# S32R372 register map
Vendor: Freescale Semiconductor, Inc.; Series: Qorivva; File version: 1.6
Registers are 32-bit, read-write, reset 0x0 unless marked. A register's access mark holds for its fields unless they carry their own. Offsets are from the block's base; [hi:lo] are bit positions; {n}, {i} and the like mark numbered series.

## LINFlexD_1 — LINFlexD
Base 0xFFE90000; register names take the prefix LINFlexD_1_
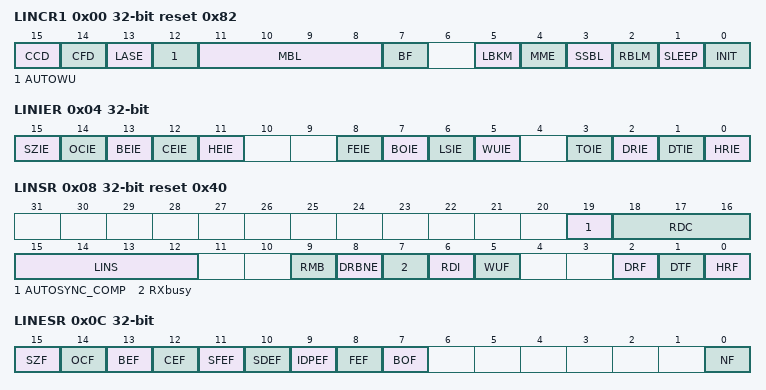
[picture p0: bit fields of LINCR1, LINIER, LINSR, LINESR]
0x00 LINCR1 reset 0x82 — LIN Control Register 1
  [15] CCD — Checksum Calculation disable This bit can be written during Initialization mode only
    0=Checksum calculation is done by hardware. When this bit is reset the LINCFR register is read only.; 1=Checksum calculation is disabled. When this bit is set the LINCFR register is read/write. User can program this register to sent a software calculated checksum/CRC (provided CFD is reset).
  [14] CFD — Checksum field disable This bit can be configured during Initialization mode only
    0=Checksum field is sent after the required number of data bytes are sent; 1=No checksum field is sent in the frame
  [13] LASE — LIN Autosynchronization Enable This bit can be programmed in Initialization mode only
    0=Autosynchronization disabled; 1=Autosynchronization enabled
  [12] AUTOWU — Auto Wakeup This bit can be configured during Initialization mode only
    0=Sleep bit is cleared by software only; 1=Sleep bit gets cleared by hardware whenever WUF bit of LINSR is set
  [11:8] MBL — Master Break Length These bits choose the length of the Sync break to be generated by the master
    {v}={v+10}-bit break length (v=0..13); 14=36-bit (cooling) break length; 15=50-bit break length
  [7] BF — By-pass filter This bit can be programmed during Initialization mode only
    0=No IRQ if ID does not match any filter; 1=A RX IRQ is generated on ID not matching any filter
  [5] LBKM — Loop Back mode Refer to "Loop back mode" in Test mode
    0=Loop Back Mode disabled; 1=Loop Back mode enabled
  [4] MME — Master mode enable This bit can be programmed in Initialization mode only
    0=Slave Mode; 1=Master Mode
  [3] SSBL — Slave Mode Sync Break Length This bit can be programmed in Initialization mode only
    0=11 bit break length; 1=10 bit break length
  [2] RBLM — Receiver Buffer Locked mode This bit can be programmed in Initialization mode only
    0=Receiver Buffer not locked, next incoming message will overwrite the old one; 1=Receiver buffer locked against overrun. Once the buffer is full the next incoming message will be discarded if buffer is not released - in other words, RMB is not reset by software.
  [1] SLEEP — Sleep Mode Request This bit is set by software to request LINFlexD to enter Sleep mode
  [0] INIT — Initialization Mode Request The software sets this bit to switch the hardware into Initialization mode
0x04 LINIER — LIN Interrupt enable register
  [15] SZIE — Stuck at zero Interrupt Enable An interrupt is generated if this bit is set and the Stuck at Zero Flag (SZF) in LINESR or UARTSR is set
    0=No interrupt; 1=Interrupt enabled
  [14] OCIE — Output Compare Interrupt Enable
    0=No interrupt; 1=Interrupt generated when OCF bit in LINESR or UARTSR is set
  [13] BEIE — Bit Error Interrupt Enable
    0=No interrupt; 1=Interrupt generated when BEF bit in LINESR is set
  [12] CEIE — Checksum Error Interrupt Enable An interrupt is generated if this bit is set and the Checksum Error Flag (CEF) is set in LINESR
    0=No interrupt; 1=Interrupt enabled
  [11] HEIE — Header Error Interrupt Enable An interrupt is generated when this bit is set and either of the following flags are set SFEF, SDEF, IDPEF in LINESR are set
    0=No interrupt; 1=Interrupt enabled
  [8] FEIE — Frame Error Interrupt Enable
    0=No interrupt; 1=Interrupt generated if Frame Error Flag (FEF) bit is set in LINESR or UARTSR
  [7] BOIE — Buffer Overrun Error Interrupt Enable An interrupt is generated if this bit is set and the Buffer Overrun Flag (BOF) is set in LINESR or UARTSR
    0=No interrupt; 1=Interrupt enabled
  [6] LSIE — LIN state Interrupt enable Interrupt is generated only when entering the above fields
    0=No interrupt; 1=Interrupt generated on entering the following states: Sync Del, Sync Field, Identifier field, Checksum
  [5] WUIE — Wakeup interrupt enable If this bit is set and the WUF in LINSR or UARTSR is set then an interrupt is generated
    0=No interrupt; 1=Interrupt enabled
  [3] TOIE — Timeout Interrupt Enable An interrupt is generated if this bit is set and UARTSR[TO] status bit is set (in UART mode)
    0=No interrupt; 1=Interrupt enabled
  [2] DRIE — Data Reception complete Interrupt enable An interrupt is generated when this bit is set and Data Received flag (DRF) in LINSR or UARTSR is set
    0=No interrupt; 1=Interrupt enabled
  [1] DTIE — Data Transmitted Interrupt enable An interrupt is generated when this bit is set and Data Transmitted flag (DTF) in LINSR or UARTSR is set
    0=No interrupt; 1=Interrupt enabled
  [0] HRIE — Header Received Interrupt An interrupt is generated when this bit is set and the Header Received flag (HRF) in LINSR is set
    0=No interrupt; 1=Interrupt enabled
0x08 LINSR reset 0x40 — LIN Status Register
  [19] AUTOSYNC_COMP — AUTOSYNC_COMP This bit is set after autosynchronization is complete and when the LASE bit in LINCR1 register is enabled
  [18:16] RDC ro — Receive Data Byte Count RDC contains the number of entries (bytes) in the Receive data buffer in LIN mode
    0=1 byte; {v}={v+1} bytes (v=1..7)
  [15:12] LINS ro — LIN state
    0=Sleep mode: LINFlexD is in Sleep mode, to save power consumption; 1=Init mode: LINFlexD is in Initialization mode; 2=Idle mode: This mode is entered when: SLEEP bit and INIT bit are reset by software; Wakeup pulse has been received on RX pin (AUTOWU set); Previous frame transmission/reception has been completed/aborted; 3=Sync break: In slave mode, a falling edge followed by a dominant state has been detected. Receiving sync break. In slave mode, a falling edge followed by a dominant state has been detected. Receiving sync break. In master mode, sync break transmission ongoing. Note: In slave mode upon any error LIN state could be either Idle or Rec Break, depending on last bit detected on LIN_RX. If last bit detected is dominant then Rec_Break, otherwise Idle.; 4=Sync Del: In Slave mode, valid Sync break has been detected (10 bit or 11 bit). Waiting for a rising edge. In Master mode, Sync break transmission has been completed, sync delimiter transmission is ongoing.; 5=Sync Field: In Slave mode, a valid sync Del has been detected (recessive state for at least one bit time). Receiving sync field. In Master mode, sync field transmission ongoing.; 6=Identifier Field: In Slave mode, a valid sync field has been received. Receiving ID field. In Master mode, identifier transmission is ongoing.; 7=Header Reception/Transmission: In Slave mode, a valid header has been received and Identifier field is available in the BIDR. In Master mode, header transmitted.; 8=Data Reception/Data Transmission: In Receiver mode, reception ongoing. In Transmitter mode, response transmission ongoing.; 9=Checksum: Data transmission/reception completed, checksum transmission/reception ongoing
  [9] RMB — Release Message Buffer
    0=Buffer data is free. Reset by hardware in when in Initialization mode; 1=Buffer data ready to be read by software. This bit should be cleared by software after reading the data received in the buffer.
  [8] DRBNE — Data Reception Buffer Not Empty Flag This bit is set by hardware as soon as the first byte of response has been received and stored in BDRL (when there is at least one data byte in reception buffer)
  [7] RXbusy ro — Receiver Busy flag In Slave mode after header reception, if DIR bit is reset and reception starts, then this bit is set
    0=Receiver is idle; 1=Reception ongoing
  [6] RDI ro — LIN Receive signal This bit reflects the current status of the Rx pin
  [5] WUF — Wakeup flag This bit is set by hardware when a falling edge is detected on the Rx pin
  [2] DRF — Data Reception Completed flag This bit is set by hardware and indicates that data reception has been completed
  [1] DTF — Data Transmission Completed flag This bit is set by hardware and indicates that data transmission is completed
  [0] HRF — Header Received flag This bit is set when the header reception is completed
0x0C LINESR — LIN Error Status Register
  [15] SZF — Stuck at Zero flag This bit is set when there is a stuck-at-zero timeout error
  [14] OCF — Output Compare Flag 0: No output compare event occurred 1: In master mode, LINESR[OCF] flag is set when counter LINTCSR[CNT] has matched the content of LINOCR[OC2]
  [13] BEF — Bit Error flag This bit is set by hardware when there is a bit error
  [12] CEF — Checksum Error flag This bit is set by hardware if the received checksum does not match the hardware-calculated checksum
  [11] SFEF — Sync Field Error flag This bit is set by hardware when the received Sync Field is inconsistent
  [10] SDEF — Sync Delimiter Error flag This bit is set by hardware when the delimiter is too short (in other words, less than one bit time)
  [9] IDPEF — ID Parity Error flag This bit is set by hardware when there is an error in the ID parity
  [8] FEF — Framing Error flag This bit is set by hardware when there is a framing error (invalid stop bit)
  [7] BOF — Buffer overrun flag This bit is set by hardware when there is a new byte received and RMB bit is not cleared
  [0] NF — Noise flag This bit is set by hardware when noise is detected in the received character
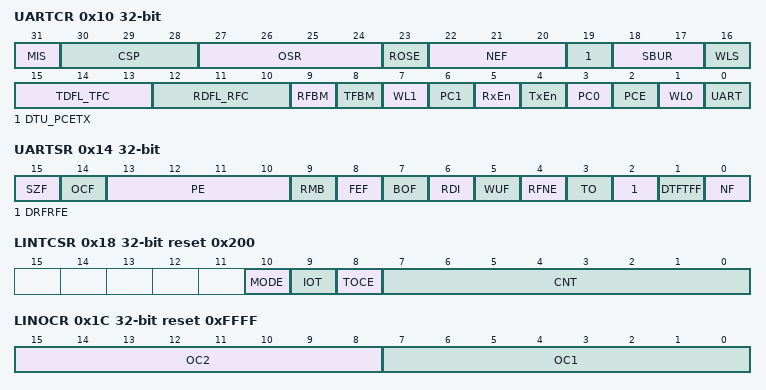
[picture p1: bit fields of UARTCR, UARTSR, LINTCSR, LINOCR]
0x10 UARTCR — UART Mode Control Register
  [31] MIS — Monitor Idle State Register bit can be read in any mode, written only in initialization mode.
    0=UARTCTO monitors the number of bits to be received; 1=UARTCTO monitors the idle state of the reception line
  [30:28] CSP — Configurable Sample Point (i) These bits will decide the sample point during reduced over sampling
  [27:24] OSR — Over Sampling Rate These bits are programmable by the user to configure the number of samples taken for a bit when reduced over sampling is enabled
  [23] ROSE — Reduced Over Sampling EnableRegister bit can be read in any mode, written only in initialization mode
    0=Each bit is over sampled sixteen times; 1=OSR bits decide the over sampling rate
  [22:20] NEF — Number of expected frame These bits are used to configure the number of expected frames in UART reception mode
  [19] DTU_PCETX — Disable Timeout in UART mode
    0=Timeout has to be handled by software; 1=Timeout in UART mode is disabled after the configured number of data frames are received
  [18:17] SBUR — Stop bits in UART reception mode When the UART is used for transmission and reception we have to set the same number of stop bits in GCR and SBUR
    0=1 stop bit; 1=2 stop bits; 2=3 stop bits
  [16] WLS — Special Word Length in UART mode This bit can be programmed in initialization mode only when the UART bit is set
    0=This bit is disabled; 1=This bit enables 12-bit + parity bit in reception (UART mode) for MSC (Micro Second Channel upstream frame) support
  [15:13] TDFL_TFC — Transmitter Data Field Length/TX FIFO Counter TDFL defines the number of bytes to be transmitted in UART buffer mode (TFBM = 0)
  [12:10] RDFL_RFC — Reception Data Field Length /RX FIFO Counter RDFL defines the number of bytes to be received in UART buffer mode (RFBM = 0)
  [9] RFBM — RFBM Rx Fifo/Buffer mode This bit can be programmed in Initialization mode, only when the UART bit is set
    0=Rx Buffer mode enabled; 1=Rx Fifo mode enabled (mandatory in DMA Rx mode)
  [8] TFBM — Tx Fifo/Buffer mode This bit can be programmed in initialization mode, only when the UART bit is set
    0=Tx Buffer mode enabled; 1=Tx Fifo mode enabled (mandatory in DMA Tx mode)
  [7] WL1 — Word Length in UART mode This bit can be programmed in Initialization mode only, when the UART bit is set
  [6] PC1 — Parity Control This bit can be programmed in Initialization mode, only when UART bit is set
  [5] RxEn — Receiver Enable This bit can be programmed only when the UART bit is set.
    0=Receiver disabled; 1=Receiver enabled
  [4] TxEn — Transmitter Enable This bit can be programmed only when UART bit is set.
    0=Transmitter disabled; 1=Transmitter enabled, transmission starts only when this bit is set and Data byte 0 (DATA0) is programmed
  [3] PC0 — Parity Control This bit can be programmed in Initialization mode, only when UART bit is set
  [2] PCE — Parity Control Enable This bit can be programmed in Initialization mode only, when the UART bit is set
    0=Parity transmit/check Disable; 1=Parity transmit/check Enable
  [1] WL0 — Word Length in UART mode This bit can be programmed in Initialization mode only, when UART bit is set
  [0] UART — UART Mode This bit can be programmed in Initialization mode only
    0=LIN mode; 1=UART mode
0x14 UARTSR — UART Mode Status Register
  [15] SZF — Stuck at Zero flag This bit is set by hardware when 100 dominant bits are detected
  [14] OCF — Output Compare Flag An interrupt will be generated if the OCIE bit in LINIER is set
    0=No output compare event occurred; 1=The content of the counter has matched the content of LINOCR
  [13:10] PE — Parity Error flag These bits indicate if there is a Parity Error in the corresponding byte
    0=No parity error; 1=Parity error in the corresponding received byte
  [9] RMB — Release Message Buffer This bit should be cleared by software
    0=Buffer data is free; 1=Buffer data ready to be read by software
  [8] FEF — Framing Error flag This bit is set by hardware when there is a framing error (invalid stop bit)
  [7] BOF — FIFO/Buffer overrun flag This bit is set by hardware when there is a new byte received and the RMB bit is not cleared in UART buffer mode
  [6] RDI — Receiver Data Input signal This bit reflects the current status of the RX pin.
  [5] WUF — Wakeup flag This bit is set by hardware when a falling edge is detected on the RX pin in sleep mode
  [4] RFNE ro — Receive FIFO Not Empty RFNE bit is set by hardware in UART FIFO mode (RFBM = 1), when there is at least one data byte present in the receive FIFO
  [3] TO — Timeout This bit is set by hardware when a UART timeout occurs - in other words, the value of UARTCTO becomes equal to the preset value of the timeout (UARTPTO register setting)
  [2] DRFRFE — Data Reception Completed Flag /Rx FIFO Empty Flag DRF is set by hardware in UART buffer mode (RFBM = 0) and indicates that the number of bytes programmed in RDFL have been received
  [1] DTFTFF — Data Transmission Completed Flag/ TX FIFO Full Flag DTF is set by hardware in UART buffer mode (TFBM = 0) and indicates that data transmission is completed
  [0] NF — Noise flag This bit is set by hardware when noise is detected in the received character
0x18 LINTCSR reset 0x200 — LIN Time-Out Control Status Register
  [10] MODE — Time-out counter mode This bit can be configured only during initialization
    0=LIN mode; 1=Output compare mode
  [9] IOT — Idle on timeout Register bit can be read in any mode, written only in initialization mode
    0=LIN state machine does not reset to Idle on timeout; 1=LIN state machine resets to Idle on timeout event
  [8] TOCE — Time-out counter enable TOCE is always configurable by software in Initialization mode
    0=Time-out counter disable. OCF flag is not set on an output compare event.; 1=Time-out counter enable. OCF flag is set if an output compare event occurs.
  [7:0] CNT ro — Counter Value These bits reflect the value of a counter used for timeout
0x1C LINOCR reset 0xFFFF — LIN Output Compare Register
  [15:8] OC2 — Output compare value 2
  [7:0] OC1 — Output compare value 1
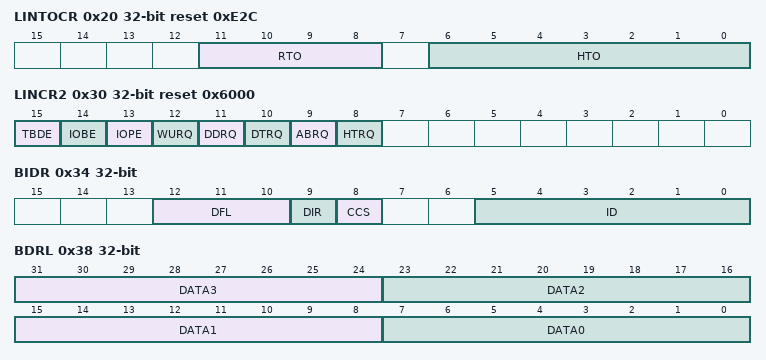
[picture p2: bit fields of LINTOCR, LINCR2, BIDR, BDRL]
0x20 LINTOCR reset 0xE2C — LIN Time-Out Control Register
  [11:8] RTO — Response timeout value This is the response timeout duration (in bit time) for 1 byte
  [6:0] HTO — Header timeout value This register contains the header timeout duration (in bit time)
0x24 LINFBRR — LIN Fractional Baud Rate Register
  [3:0] FBR — Fractional Baud rates Register bit can be read in any mode, written only in initialization mode.
    0=Fraction(LDIV) = 0; {v}=Fraction(LDIV) = {v}/16 (v=1..15)
0x28 LINIBRR — LIN Integer Baud Rate Register
  [19:0] IBR — Integer Baud rates These bits along with the fractional baud rate bits decide the LIN baud rate
0x2C LINCFR — LIN Checksum Field Register
  [7:0] CF — Checksum bits When the CCD bit is reset these bits are read-only and are calculated by hardware
0x30 LINCR2 reset 0x6000 — LIN Control Register 2
  [15] TBDE — Two Bit delimiter bit This bit can be set in Initialization mode only
    0=Delimiter length in break field is 1 bit; 1=Delimiter length in break field is 2 bits
  [14] IOBE — Idle on Bit Error This bit can be set in Initialization mode only
    0=Bit Error does not reset LIN state machine; 1=Bit Error resets LIN state machine
  [13] IOPE — Idle on Identifier Parity Error This bit can be set in Initialization mode only
    0=Parity Error does not reset LIN state machine; 1=Parity Error resets LIN state machine
  [12] WURQ — Wakeup Generate Request Setting this bit will generate a wakeup pulse
  [11] DDRQ — Data Discard request Set by software to stop data reception if the frame does not concern the node
  [10] DTRQ — Data Transmission Request Set by software in slave mode to request the transmission of the LIN Data field stored in the Buffer data register
  [9] ABRQ — Abort Request Set by software to abort the current transmission
  [8] HTRQ — Header Transmission Request Set by software to request the transmission of the LIN Header
0x34 BIDR — Buffer Identifier Register
  [12:10] DFL — Data Field Length Number of data bytes in the response part of the frame
  [9] DIR — Direction This bit controls the direction of the data field.
    0=LINFlexD receives the data and copy them in the BDR registers; 1=LINFlexD transmits the data from the BDR registers
  [8] CCS — Classic Checksum This bit controls the type of checksum applied on the current message.
    0=Enhanced Checksum covering Identifier and Data fields. This is compatible with LIN specification rev. 2.0 and higher.; 1=Classic Checksum covering Data filed only. This is compatible with LIN specification 1.3 and lower.
  [5:0] ID — Identifier Identifier part of the identifier field without the identifier parity
0x38 BDRL — Buffer Data Register Least Significant
  [31:24] DATA3 — Data Byte 3 Data byte 3 of the data field.
  [23:16] DATA2 — Data Byte 2 Data byte 2 of the data field.
  [15:8] DATA1 — Data Byte 1 Data byte 1of the data field.
  [7:0] DATA0 — Data Byte 0 Data byte 0 of the data field.
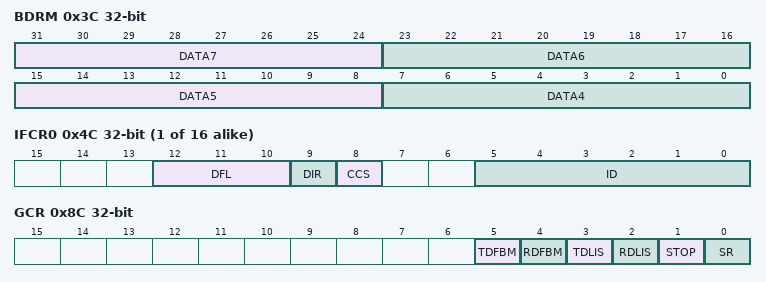
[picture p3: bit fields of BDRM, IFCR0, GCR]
0x3C BDRM — Buffer Data Register Most Significant
  [31:24] DATA7 — Data Byte 7 Data byte 7 of the data field.
  [23:16] DATA6 — Data Byte 6 Data byte 6 of the data field.
  [15:8] DATA5 — Data Byte 5 Data byte 5of the data field.
  [7:0] DATA4 — Data Byte 4 Data byte 4 of the data field.
0x40 IFER — Identifier Filter Enable Register
  [15:0] FACT — Filter active The software sets the bit FACT[x] to activate the filter x in Identifier list mode
0x44 IFMI ro — Identifier Filter Match Index
  [4:0] IFMI — Filter match index Upon a filter match with xth filter - IFMI[4:0] = x+1
0x48 IFMR — Identifier Filter Mode Register
  [7:0] IFM — Filter mode Register bit can be read in any mode, written only in initialization mode.
    0=Filters 2n and 2n+1 are in identifier list mode; 1=Filters 2n and 2n+1 are in mask mode, where filter 2n+1 is the mask for filter 2n
{0x4C+4i} IFCR{i} (i=0..15) — Identifier Filter Control Register
  [12:10] DFL — Data Field Length
  [9] DIR — Direction
    0=LINFlexD receives data and copies to the BDR registers; 1=LINFlexD transmits data from the BDR registers
  [8] CCS — Classic Checksum
    0=Enhanced Checksum covering Identifier and Data fields. This is compatible with LIN specification rev. 2.0 and higher.; 1=Classic Checksum covering Data field only. This is compatible with LIN specification 1.3 and lower.
  [5:0] ID — Identifier
0x8C GCR — Global Control Register
  [5] TDFBM — Transmit data first bit MSB This bit controls the first bit of transmit data (payload only) as MSB/LSB in both UART and LIN modes
    0=The first bit of transmitted data is LSB - in other words, the first bit transmitted is mapped on LSB bit (BDR (0), BDR (8), BDR (16), BDR (24)); 1=The first bit of transmitted data is MSB - in other words, the first bit transmitted is mapped on MSB bit (BDR (7), BDR (15), BDR (23), BDR (31))
  [4] RDFBM — Received data first bit MSB This bit controls the first bit of received data (payload only) as MSB/LSB both in UART and LIN modes
    0=The first bit of received data is LSB - in other words, the first bit received is mapped on LSB bit (BDR (0), BDR (8), BDR (16), BDR (24)); 1=The first bit of received data is MSB - in other words, the first bit received is mapped on MSB bit (BDR (7), BDR (15), BDR (23), BDR (31))
  [3] TDLIS — Transmit data level inversion selection This bit controls the data inversion of transmitted data (payload only) in both UART and LIN modes
    0=Transmitted data is not inverted; 1=Transmitted data is inverted
  [2] RDLIS — Received data level inversion selection This bit controls the data inversion of received data (payload only) in both UART and LIN modes
    0=Received data is not inverted; 1=Received data is inverted
  [1] STOP — 1/2 stop bit configuration This bit controls the number of stop bit transmitted data in both UART and LIN modes
    0=1 stop bit; 1=2 stop bits
  [0] SR — Soft reset SR executes a soft reset of the LINFlexD controller (FSMs, FIFO pointers, counters, timers, status and error registers) without modifying the configuration registers when a 1 write operation is performed
0x90 UARTPTO reset 0xFFF — UART Preset Timeout Register
  [11:0] PTO — Preset Timeout PTO defines the preset value of timeout counter
0x94 UARTCTO ro — UART Current Timeout Register
  [11:0] CTO — Current Timeout CTO defines the current value of the timeout counter
0x98 DMATXE — DMA Tx Enable Register
  [15:0] DTE — DMA Tx channel Y enable The actual size of the register DMATXE depends on the value of the static parameter TX_CH_NUM
    0=DMA Tx channel Y disabled; 1=DMA Tx channel Y enabled
0x9C DMARXE — DMA Rx Enable Register
  [15:0] DRE — DMA Rx channel Y enable The actual size of the register DMARXE depends on the value of the static parameter RX_CH_NUM
    0=DMA Rx channel Y disabled; 1=DMA Rx channel Y enabled
